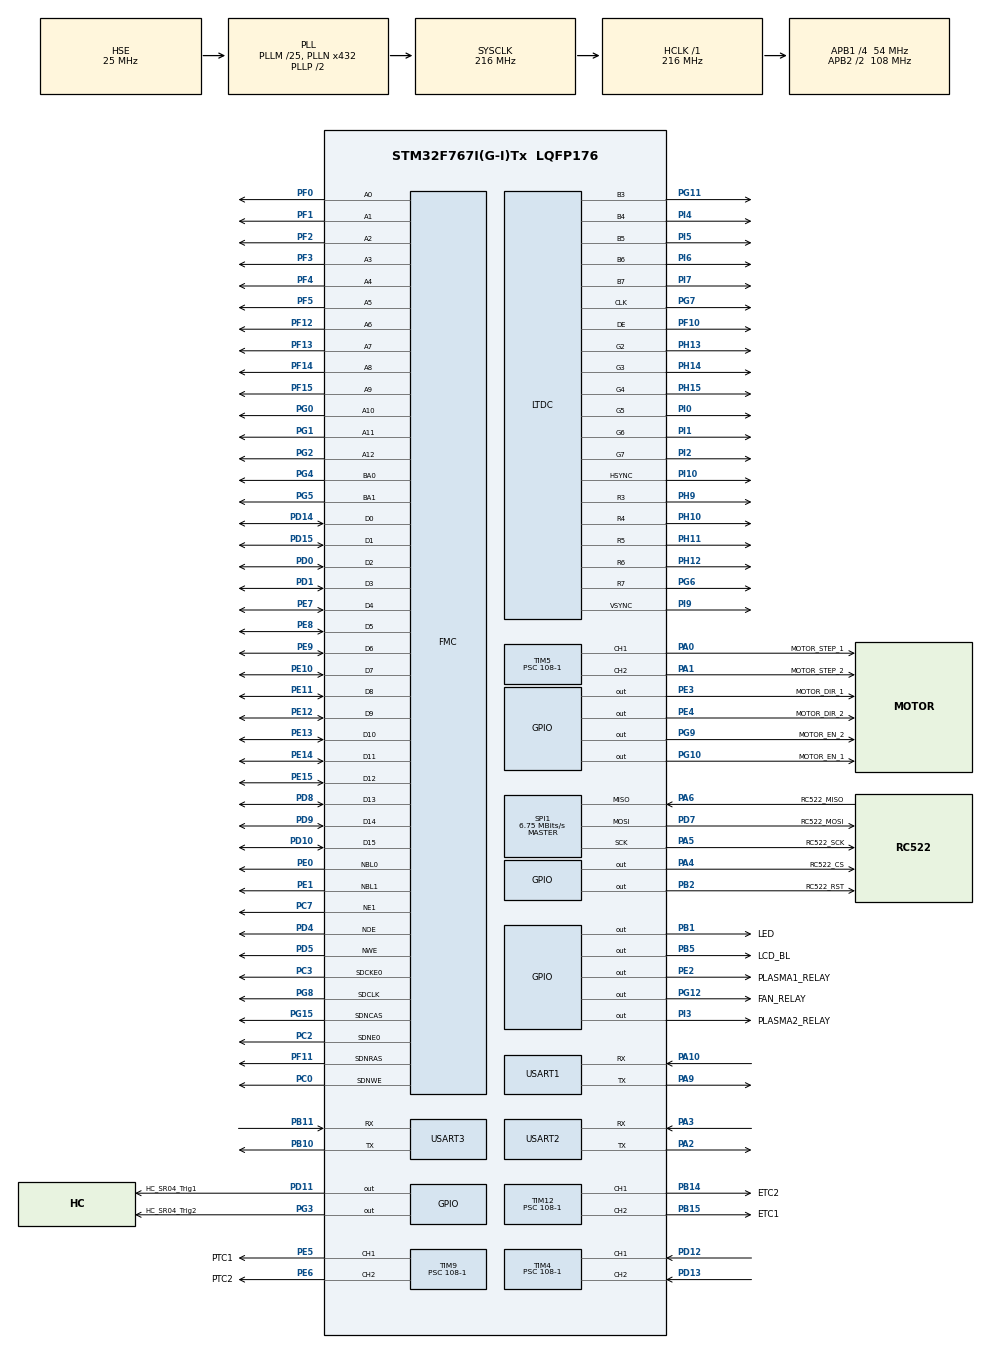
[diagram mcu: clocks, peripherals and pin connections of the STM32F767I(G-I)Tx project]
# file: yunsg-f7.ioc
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CORTEX_M7.CPU_DCache=Enabled
CORTEX_M7.CPU_ICache=Enabled
CORTEX_M7.Enable_Spec=__NULL
CORTEX_M7.MPU_Control=__NULL
CORTEX_M7.default_mode_Activation=1
DMA2D.ColorMode=DMA2D_OUTPUT_RGB565
Dma.Request0=USART2_RX
Dma.Request1=USART2_TX
Dma.USART2_RX.0.Direction=DMA_PERIPH_TO_MEMORY
Dma.USART2_RX.0.FIFOMode=DMA_FIFOMODE_DISABLE
Dma.USART2_RX.0.Instance=DMA1_Stream5
Dma.USART2_RX.0.MemDataAlignment=DMA_MDATAALIGN_BYTE
Dma.USART2_RX.0.MemInc=DMA_MINC_ENABLE
Dma.USART2_RX.0.Mode=DMA_NORMAL
Dma.USART2_RX.0.PeriphDataAlignment=DMA_PDATAALIGN_BYTE
Dma.USART2_RX.0.PeriphInc=DMA_PINC_DISABLE
Dma.USART2_RX.0.Priority=DMA_PRIORITY_LOW
Dma.USART2_TX.1.Direction=DMA_MEMORY_TO_PERIPH
Dma.USART2_TX.1.FIFOMode=DMA_FIFOMODE_DISABLE
Dma.USART2_TX.1.Instance=DMA1_Stream6
Dma.USART2_TX.1.MemDataAlignment=DMA_MDATAALIGN_BYTE
Dma.USART2_TX.1.MemInc=DMA_MINC_ENABLE
Dma.USART2_TX.1.Mode=DMA_NORMAL
Dma.USART2_TX.1.PeriphDataAlignment=DMA_PDATAALIGN_BYTE
Dma.USART2_TX.1.PeriphInc=DMA_PINC_DISABLE
Dma.USART2_TX.1.Priority=DMA_PRIORITY_LOW
FMC.AddressSetupTime1=0x0F
FMC.BusTurnAroundDuration1=0
FMC.CASLatency1=FMC_SDRAM_CAS_LATENCY_3
FMC.ColumnBitsNumber1=FMC_SDRAM_COLUMN_BITS_NUM_9
FMC.DataSetupTime1=80
FMC.ExitSelfRefreshDelay1=8
FMC.ExtendedAddressSetupTime1=0x0F
FMC.ExtendedBusTurnAroundDuration1=0
FMC.ExtendedDataSetupTime1=0x0F
FMC.ExtendedMode1=FMC_EXTENDED_MODE_ENABLE
FMC.LoadToActiveDelay1=2
FMC.RCDDelay1=2
FMC.RPDelay1=2
FMC.ReadBurst1=FMC_SDRAM_RBURST_ENABLE
FMC.ReadPipeDelay1=FMC_SDRAM_RPIPE_DELAY_1
FMC.RowCycleDelay1=6
FMC.SDClockPeriod1=FMC_SDRAM_CLOCK_PERIOD_2
FMC.SelfRefreshTime1=6
FMC.WriteFifo1=FMC_WRITE_FIFO_DISABLE
FMC.WriteRecoveryTime1=4
FREERTOS.Tasks01=defaultTask,24,128,StartDefaultTask,Default,NULL,Dynamic,NULL,NULL
IWDG.Prescaler=IWDG_PRESCALER_64
LTDC.ActiveW=800
LTDC.Alpha_L0=255
LTDC.FBStartAdress_L0=0xc0000000
LTDC.HBP=88
LTDC.HFP=40
LTDC.HSync=48
LTDC.ImageHeight_L0=480
LTDC.ImageWidth_L0=800
LTDC.Layers=0
LTDC.PixelFormat_L0=LTDC_PIXEL_FORMAT_RGB565
LTDC.VBP=32
LTDC.VFP=13
LTDC.VSync=3
LTDC.WindowX1_L0=800
LTDC.WindowY1_L0=480
Mcu.Family=STM32F7
Mcu.Name=STM32F767I(G-I)Tx
Mcu.Package=LQFP176
NVIC.DMA1_Stream5_IRQn=true\:5\:0\:false\:false\:true\:true\:false\:true\:true
NVIC.DMA1_Stream6_IRQn=true\:5\:0\:false\:false\:true\:true\:false\:true\:true
NVIC.DMA2D_IRQn=true\:5\:0\:false\:false\:true\:true\:true\:true\:true
NVIC.LTDC_IRQn=true\:5\:0\:false\:false\:true\:true\:true\:true\:true
NVIC.PriorityGroup=NVIC_PRIORITYGROUP_4
NVIC.TIM1_UP_TIM10_IRQn=true\:15\:0\:false\:false\:true\:false\:false\:true\:true
NVIC.TIM2_IRQn=true\:5\:0\:false\:false\:true\:true\:true\:true\:true
NVIC.TIM4_IRQn=true\:5\:0\:true\:false\:true\:true\:true\:true\:true
NVIC.TimeBase=TIM1_UP_TIM10_IRQn
NVIC.TimeBaseIP=TIM1
NVIC.USART2_IRQn=true\:5\:0\:false\:false\:true\:true\:true\:true\:true
NVIC.USART3_IRQn=true\:5\:0\:false\:false\:true\:true\:true\:true\:true
PA0/WKUP.GPIO_Label=MOTOR_STEP_1
PA0/WKUP.Signal=S_TIM5_CH1
PA1.GPIO_Label=MOTOR_STEP_2
PA1.Signal=S_TIM5_CH2
PA10.Mode=Asynchronous
PA10.Signal=USART1_RX
PA13.Mode=Serial_Wire
PA13.Signal=SYS_JTMS-SWDIO
PA14.Mode=Serial_Wire
PA14.Signal=SYS_JTCK-SWCLK
PA2.Mode=Asynchronous
PA2.Signal=USART2_TX
PA3.Mode=Asynchronous
PA3.Signal=USART2_RX
PA4.GPIO_Label=RC522_CS
PA4.Signal=GPIO_Output
PA5.GPIO_Label=RC522_SCK
PA5.Mode=Full_Duplex_Master
PA5.Signal=SPI1_SCK
PA6.GPIO_Label=RC522_MISO
PA6.Mode=Full_Duplex_Master
PA6.Signal=SPI1_MISO
PA9.Mode=Asynchronous
PA9.Signal=USART1_TX
PB1.GPIO_Label=LED
PB1.Signal=GPIO_Output
PB10.Mode=Asynchronous
PB10.Signal=USART3_TX
PB11.Mode=Asynchronous
PB11.Signal=USART3_RX
PB14.GPIO_Label=ETC2
PB14.Signal=S_TIM12_CH1
PB15.GPIO_Label=ETC1
PB15.Signal=S_TIM12_CH2
PB2.GPIO_Label=RC522_RST
PB2.Signal=GPIO_Output
PB5.GPIO_Label=LCD_BL
PB5.GPIO_Speed=GPIO_SPEED_FREQ_HIGH
PB5.Signal=GPIO_Output
PC0.Signal=FMC_SDNWE
PC1.GPIO_Label=ULTRAVIOLET_SENSOR
PC1.Signal=ADCx_IN11
PC14/OSC32_IN.Mode=LSE-External-Oscillator
PC14/OSC32_IN.Signal=RCC_OSC32_IN
PC15/OSC32_OUT.Mode=LSE-External-Oscillator
PC15/OSC32_OUT.Signal=RCC_OSC32_OUT
PC2.Mode=SdramChipSelect1_1
PC2.Signal=FMC_SDNE0
PC3.Mode=SdramChipSelect1_1
PC3.Signal=FMC_SDCKE0
PC7.Mode=NorPsramChipSelect1_1
PC7.Signal=FMC_NE1
PD0.Signal=FMC_D2_DA2
PD1.Signal=FMC_D3_DA3
PD10.Signal=FMC_D15_DA15
PD11.GPIO_Label=HC_SR04_Trig1
PD11.Signal=GPIO_Output
PD12.Signal=S_TIM4_CH1
PD13.Signal=S_TIM4_CH2
PD14.Signal=FMC_D0_DA0
PD15.Signal=FMC_D1_DA1
PD4.Signal=FMC_NOE
PD5.Signal=FMC_NWE
PD7.GPIO_Label=RC522_MOSI
PD7.Mode=Full_Duplex_Master
PD7.Signal=SPI1_MOSI
PD8.Signal=FMC_D13_DA13
PD9.Signal=FMC_D14_DA14
PE0.Signal=FMC_NBL0
PE1.Signal=FMC_NBL1
PE10.Signal=FMC_D7_DA7
PE11.Signal=FMC_D8_DA8
PE12.Signal=FMC_D9_DA9
PE13.Signal=FMC_D10_DA10
PE14.Signal=FMC_D11_DA11
PE15.Signal=FMC_D12_DA12
PE2.GPIO_Label=PLASMA1_RELAY
PE2.GPIO_ModeDefaultOutputPP=GPIO_MODE_OUTPUT_OD
PE2.GPIO_PuPd=GPIO_NOPULL
PE2.PinState=GPIO_PIN_SET
PE2.Signal=GPIO_Output
PE3.GPIO_Label=MOTOR_DIR_1
PE3.Signal=GPIO_Output
PE4.GPIO_Label=MOTOR_DIR_2
PE4.Signal=GPIO_Output
PE5.GPIO_Label=PTC1
PE5.Signal=S_TIM9_CH1
PE6.GPIO_Label=PTC2
PE6.Signal=S_TIM9_CH2
PE7.Signal=FMC_D4_DA4
PE8.Signal=FMC_D5_DA5
PE9.Signal=FMC_D6_DA6
PF0.Signal=FMC_A0
PF1.Signal=FMC_A1
PF10.GPIO_Speed=GPIO_SPEED_FREQ_VERY_HIGH
PF10.Mode=RGB565
PF10.Signal=LTDC_DE
PF11.Signal=FMC_SDNRAS
PF12.Signal=FMC_A6
PF13.Signal=FMC_A7
PF14.Signal=FMC_A8
PF15.Signal=FMC_A9
PF2.Signal=FMC_A2
PF3.Signal=FMC_A3
PF4.Signal=FMC_A4
PF5.Signal=FMC_A5
PG0.Signal=FMC_A10
PG1.Signal=FMC_A11
PG10.GPIO_Label=MOTOR_EN_1
PG10.Signal=GPIO_Output
PG11.GPIO_Speed=GPIO_SPEED_FREQ_VERY_HIGH
PG11.Mode=RGB565
PG11.Signal=LTDC_B3
PG12.GPIO_Label=FAN_RELAY
PG12.GPIO_ModeDefaultOutputPP=GPIO_MODE_OUTPUT_OD
PG12.GPIO_PuPd=GPIO_NOPULL
PG12.PinState=GPIO_PIN_SET
PG12.Signal=GPIO_Output
PG15.Signal=FMC_SDNCAS
PG2.Signal=FMC_A12
PG3.GPIO_Label=HC_SR04_Trig2
PG3.Signal=GPIO_Output
PG4.Signal=FMC_A14_BA0
PG5.Signal=FMC_A15_BA1
PG6.GPIO_Speed=GPIO_SPEED_FREQ_VERY_HIGH
PG6.Mode=RGB565
PG6.Signal=LTDC_R7
PG7.GPIO_Speed=GPIO_SPEED_FREQ_VERY_HIGH
PG7.Mode=RGB565
PG7.Signal=LTDC_CLK
PG8.Signal=FMC_SDCLK
PG9.GPIO_Label=MOTOR_EN_2
PG9.Signal=GPIO_Output
PH0/OSC_IN.Mode=HSE-External-Oscillator
PH0/OSC_IN.Signal=RCC_OSC_IN
PH1/OSC_OUT.Mode=HSE-External-Oscillator
PH1/OSC_OUT.Signal=RCC_OSC_OUT
PH10.GPIO_Speed=GPIO_SPEED_FREQ_VERY_HIGH
PH10.Mode=RGB565
PH10.Signal=LTDC_R4
PH11.GPIO_Speed=GPIO_SPEED_FREQ_VERY_HIGH
PH11.Mode=RGB565
PH11.Signal=LTDC_R5
PH12.GPIO_Speed=GPIO_SPEED_FREQ_VERY_HIGH
PH12.Mode=RGB565
PH12.Signal=LTDC_R6
PH13.GPIO_Speed=GPIO_SPEED_FREQ_VERY_HIGH
PH13.Mode=RGB565
PH13.Signal=LTDC_G2
PH14.GPIO_Speed=GPIO_SPEED_FREQ_VERY_HIGH
PH14.Mode=RGB565
PH14.Signal=LTDC_G3
PH15.GPIO_Speed=GPIO_SPEED_FREQ_VERY_HIGH
PH15.Mode=RGB565
PH15.Signal=LTDC_G4
PH9.GPIO_Speed=GPIO_SPEED_FREQ_VERY_HIGH
PH9.Mode=RGB565
PH9.Signal=LTDC_R3
PI0.GPIO_Speed=GPIO_SPEED_FREQ_VERY_HIGH
PI0.Mode=RGB565
PI0.Signal=LTDC_G5
PI1.GPIO_Speed=GPIO_SPEED_FREQ_VERY_HIGH
PI1.Mode=RGB565
PI1.Signal=LTDC_G6
PI10.GPIO_Speed=GPIO_SPEED_FREQ_VERY_HIGH
PI10.Mode=RGB565
PI10.Signal=LTDC_HSYNC
PI2.GPIO_Speed=GPIO_SPEED_FREQ_VERY_HIGH
PI2.Mode=RGB565
PI2.Signal=LTDC_G7
PI3.GPIO_Label=PLASMA2_RELAY
PI3.GPIO_ModeDefaultOutputPP=GPIO_MODE_OUTPUT_OD
PI3.GPIO_PuPd=GPIO_NOPULL
PI3.GPIO_Speed=GPIO_SPEED_FREQ_MEDIUM
PI3.PinState=GPIO_PIN_SET
PI3.Signal=GPIO_Output
PI4.GPIO_Speed=GPIO_SPEED_FREQ_VERY_HIGH
PI4.Mode=RGB565
PI4.Signal=LTDC_B4
PI5.GPIO_Speed=GPIO_SPEED_FREQ_VERY_HIGH
PI5.Mode=RGB565
PI5.Signal=LTDC_B5
PI6.GPIO_Speed=GPIO_SPEED_FREQ_VERY_HIGH
PI6.Mode=RGB565
PI6.Signal=LTDC_B6
PI7.GPIO_Speed=GPIO_SPEED_FREQ_VERY_HIGH
PI7.Mode=RGB565
PI7.Signal=LTDC_B7
PI9.GPIO_Speed=GPIO_SPEED_FREQ_VERY_HIGH
PI9.Mode=RGB565
PI9.Signal=LTDC_VSYNC
ProjectManager.HeapSize=0x200
ProjectManager.StackSize=0x1000
ProjectManager.TargetToolchain=Makefile
RCC.AHBFreq_Value=216000000
RCC.APB1CLKDivider=RCC_HCLK_DIV4
RCC.APB1Freq_Value=54000000
RCC.APB1TimFreq_Value=108000000
RCC.APB2CLKDivider=RCC_HCLK_DIV2
RCC.APB2Freq_Value=108000000
RCC.APB2TimFreq_Value=216000000
RCC.CortexFreq_Value=216000000
RCC.HCLKFreq_Value=216000000
RCC.HSE_VALUE=25000000
RCC.HSI_VALUE=16000000
RCC.PLLM=25
RCC.PLLN=432
RCC.PLLSourceVirtual=RCC_PLLSOURCE_HSE
RCC.SYSCLKFreq_VALUE=216000000
RCC.SYSCLKSource=RCC_SYSCLKSOURCE_PLLCLK
RCC.USBFreq_Value=216000000
RCC.VCOOutputFreq_Value=432000000
SH.ADCx_IN11.0=ADC1_IN11
SH.FMC_A0.0=FMC_A0,13b-sda1
SH.FMC_A1.0=FMC_A1,13b-sda1
SH.FMC_A10.0=FMC_A10,13b-sda1
SH.FMC_A11.0=FMC_A11,13b-sda1
SH.FMC_A12.0=FMC_A12,13b-sda1
SH.FMC_A14_BA0.0=FMC_BA0,FourSdramBanks1
SH.FMC_A15_BA1.0=FMC_BA1,FourSdramBanks1
SH.FMC_A2.0=FMC_A2,13b-sda1
SH.FMC_A3.0=FMC_A3,13b-sda1
SH.FMC_A4.0=FMC_A4,13b-sda1
SH.FMC_A5.0=FMC_A5,13b-sda1
SH.FMC_A6.0=FMC_A6,13b-sda1
SH.FMC_A6.1=FMC_A6,A6_1
SH.FMC_A7.0=FMC_A7,13b-sda1
SH.FMC_A8.0=FMC_A8,13b-sda1
SH.FMC_A9.0=FMC_A9,13b-sda1
SH.FMC_D0_DA0.0=FMC_D0,sd-16b-d1
SH.FMC_D0_DA0.1=FMC_D0,16b-d1
SH.FMC_D10_DA10.0=FMC_D10,sd-16b-d1
SH.FMC_D10_DA10.1=FMC_D10,16b-d1
SH.FMC_D11_DA11.0=FMC_D11,sd-16b-d1
SH.FMC_D11_DA11.1=FMC_D11,16b-d1
SH.FMC_D12_DA12.0=FMC_D12,sd-16b-d1
SH.FMC_D12_DA12.1=FMC_D12,16b-d1
SH.FMC_D13_DA13.0=FMC_D13,sd-16b-d1
SH.FMC_D13_DA13.1=FMC_D13,16b-d1
SH.FMC_D14_DA14.0=FMC_D14,sd-16b-d1
SH.FMC_D14_DA14.1=FMC_D14,16b-d1
SH.FMC_D15_DA15.0=FMC_D15,sd-16b-d1
SH.FMC_D15_DA15.1=FMC_D15,16b-d1
SH.FMC_D1_DA1.0=FMC_D1,sd-16b-d1
SH.FMC_D1_DA1.1=FMC_D1,16b-d1
SH.FMC_D2_DA2.0=FMC_D2,sd-16b-d1
SH.FMC_D2_DA2.1=FMC_D2,16b-d1
SH.FMC_D3_DA3.0=FMC_D3,sd-16b-d1
SH.FMC_D3_DA3.1=FMC_D3,16b-d1
SH.FMC_D4_DA4.0=FMC_D4,sd-16b-d1
SH.FMC_D4_DA4.1=FMC_D4,16b-d1
SH.FMC_D5_DA5.0=FMC_D5,sd-16b-d1
SH.FMC_D5_DA5.1=FMC_D5,16b-d1
SH.FMC_D6_DA6.0=FMC_D6,sd-16b-d1
SH.FMC_D6_DA6.1=FMC_D6,16b-d1
SH.FMC_D7_DA7.0=FMC_D7,sd-16b-d1
SH.FMC_D7_DA7.1=FMC_D7,16b-d1
SH.FMC_D8_DA8.0=FMC_D8,sd-16b-d1
SH.FMC_D8_DA8.1=FMC_D8,16b-d1
SH.FMC_D9_DA9.0=FMC_D9,sd-16b-d1
SH.FMC_D9_DA9.1=FMC_D9,16b-d1
SH.FMC_NBL0.0=FMC_NBL0,Sd2ByteEnable1
SH.FMC_NBL1.0=FMC_NBL1,Sd2ByteEnable1
SH.FMC_NOE.0=FMC_NOE,Lcd1
SH.FMC_NWE.0=FMC_NWE,Lcd1
SH.FMC_SDCLK.0=FMC_SDCLK,13b-sda1
SH.FMC_SDNCAS.0=FMC_SDNCAS,13b-sda1
SH.FMC_SDNRAS.0=FMC_SDNRAS,13b-sda1
SH.FMC_SDNWE.0=FMC_SDNWE,13b-sda1
SH.S_TIM12_CH1.0=TIM12_CH1,PWM Generation1 CH1
SH.S_TIM12_CH2.0=TIM12_CH2,PWM Generation2 CH2
SH.S_TIM4_CH1.0=TIM4_CH1,Input_Capture1_from_TI1
SH.S_TIM4_CH2.0=TIM4_CH2,Input_Capture2_from_TI2
SH.S_TIM5_CH1.0=TIM5_CH1,PWM Generation1 CH1
SH.S_TIM5_CH2.0=TIM5_CH2,PWM Generation2 CH2
SH.S_TIM9_CH1.0=TIM9_CH1,PWM Generation1 CH1
SH.S_TIM9_CH2.0=TIM9_CH2,PWM Generation2 CH2
SPI1.BaudRatePrescaler=SPI_BAUDRATEPRESCALER_16
SPI1.CalculateBaudRate=6.75 MBits/s
SPI1.DataSize=SPI_DATASIZE_8BIT
SPI1.Direction=SPI_DIRECTION_2LINES
SPI1.Mode=SPI_MODE_MASTER
SPI1.VirtualType=VM_MASTER
TIM12.Channel-PWM\ Generation1\ CH1=TIM_CHANNEL_1
TIM12.Channel-PWM\ Generation2\ CH2=TIM_CHANNEL_2
TIM12.Period=1000-1
TIM12.Prescaler=108-1
TIM2.Period=18000000-1
TIM2.Prescaler=10800-1
TIM4.Channel-Input_Capture1_from_TI1=TIM_CHANNEL_1
TIM4.Channel-Input_Capture2_from_TI2=TIM_CHANNEL_2
TIM4.Prescaler=108-1
TIM5.Channel-PWM\ Generation1\ CH1=TIM_CHANNEL_1
TIM5.Channel-PWM\ Generation2\ CH2=TIM_CHANNEL_2
TIM5.Period=1000-1
TIM5.Prescaler=108-1
TIM5.Pulse-PWM\ Generation1\ CH1=500
TIM5.Pulse-PWM\ Generation2\ CH2=500
TIM9.Channel-PWM\ Generation1\ CH1=TIM_CHANNEL_1
TIM9.Channel-PWM\ Generation2\ CH2=TIM_CHANNEL_2
TIM9.Period=1000-1
TIM9.Prescaler=108-1
USART1.VirtualMode-Asynchronous=VM_ASYNC
USART2.VirtualMode-Asynchronous=VM_ASYNC
USART3.VirtualMode-Asynchronous=VM_ASYNC
VP_CRC_VS_CRC.Mode=CRC_Activate
VP_DMA2D_VS_DMA2D.Mode=DMA2D_Activate
VP_FREERTOS_VS_CMSIS_V2.Mode=CMSIS_V2
VP_IWDG_VS_IWDG.Mode=IWDG_Activate
VP_SYS_VS_tim1.Mode=TIM1
VP_TIM12_VS_ClockSourceINT.Mode=Internal
VP_TIM2_VS_ClockSourceINT.Mode=Internal
VP_TIM4_VS_ClockSourceINT.Mode=Internal
VP_TIM5_VS_ClockSourceINT.Mode=Internal
VP_TIM9_VS_ClockSourceINT.Mode=Internal
board=custom

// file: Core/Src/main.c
/* USER CODE BEGIN Header */
/**
 ******************************************************************************
 * @file           : main.c
 * @brief          : Main program body
 ******************************************************************************
 * @attention
 *
 * Copyright (c) 2025 STMicroelectronics.
 * All rights reserved.
 *
 * This software is licensed under terms that can be found in the LICENSE file
 * in the root directory of this software component.
 * If no LICENSE file comes with this software, it is provided AS-IS.
 *
 ******************************************************************************
 */
/* USER CODE END Header */
#include "main.h"
#include "cmsis_os.h"
#include "crc.h"
#include "dma.h"
#include "dma2d.h"
#include "iwdg.h"
#include "ltdc.h"
#include "spi.h"
#include "tim.h"
#include "usart.h"
#include "gpio.h"
#include "fmc.h"

void SystemClock_Config(void);
void MX_FREERTOS_Init(void);

int main(void)
{

  /* Enable the CPU Cache */

  /* Enable I-Cache---------------------------------------------------------*/
  SCB_EnableICache();

  /* Enable D-Cache---------------------------------------------------------*/
  SCB_EnableDCache();

  /* MCU Configuration--------------------------------------------------------*/

  /* Reset of all peripherals, Initializes the Flash interface and the Systick. */
  HAL_Init();

  /* Configure the system clock */
  SystemClock_Config();

  /* Initialize all configured peripherals */
  MX_GPIO_Init();
  MX_DMA_Init();
  MX_USART1_UART_Init();
  MX_DMA2D_Init();
  MX_FMC_Init();
  MX_LTDC_Init();
  MX_CRC_Init();
  MX_USART2_UART_Init();
  MX_TIM4_Init();
  MX_TIM5_Init();
  MX_SPI1_Init();
  MX_USART3_UART_Init();
  MX_TIM2_Init();
  MX_IWDG_Init();
  MX_TIM12_Init();
  MX_TIM9_Init();

  /* Init scheduler */
  osKernelInitialize();

  /* Call init function for freertos objects (in cmsis_os2.c) */
  MX_FREERTOS_Init();

  /* Start scheduler */
  osKernelStart();

  /* We should never get here as control is now taken by the scheduler */

  /* Infinite loop */
  while (1)
  {

  }
}

void SystemClock_Config(void)
{
  RCC_OscInitTypeDef RCC_OscInitStruct = {0};
  RCC_ClkInitTypeDef RCC_ClkInitStruct = {0};

  /** Configure LSE Drive Capability
  */
  HAL_PWR_EnableBkUpAccess();

  /** Configure the main internal regulator output voltage
  */
  __HAL_RCC_PWR_CLK_ENABLE();
  __HAL_PWR_VOLTAGESCALING_CONFIG(PWR_REGULATOR_VOLTAGE_SCALE1);

  /** Initializes the RCC Oscillators according to the specified parameters
  * in the RCC_OscInitTypeDef structure.
  */
  RCC_OscInitStruct.OscillatorType = RCC_OSCILLATORTYPE_LSI|RCC_OSCILLATORTYPE_HSE;
  RCC_OscInitStruct.HSEState = RCC_HSE_ON;
  RCC_OscInitStruct.LSIState = RCC_LSI_ON;
  RCC_OscInitStruct.PLL.PLLState = RCC_PLL_ON;
  RCC_OscInitStruct.PLL.PLLSource = RCC_PLLSOURCE_HSE;
  RCC_OscInitStruct.PLL.PLLM = 25;
  RCC_OscInitStruct.PLL.PLLN = 432;
  RCC_OscInitStruct.PLL.PLLP = RCC_PLLP_DIV2;
  RCC_OscInitStruct.PLL.PLLQ = 2;
  RCC_OscInitStruct.PLL.PLLR = 2;
  if (HAL_RCC_OscConfig(&RCC_OscInitStruct) != HAL_OK)
  {
    Error_Handler();
  }

  /** Activate the Over-Drive mode
  */
  if (HAL_PWREx_EnableOverDrive() != HAL_OK)
  {
    Error_Handler();
  }

  /** Initializes the CPU, AHB and APB buses clocks
  */
  RCC_ClkInitStruct.ClockType = RCC_CLOCKTYPE_HCLK|RCC_CLOCKTYPE_SYSCLK
                              |RCC_CLOCKTYPE_PCLK1|RCC_CLOCKTYPE_PCLK2;
  RCC_ClkInitStruct.SYSCLKSource = RCC_SYSCLKSOURCE_PLLCLK;
  RCC_ClkInitStruct.AHBCLKDivider = RCC_SYSCLK_DIV1;
  RCC_ClkInitStruct.APB1CLKDivider = RCC_HCLK_DIV4;
  RCC_ClkInitStruct.APB2CLKDivider = RCC_HCLK_DIV2;

  if (HAL_RCC_ClockConfig(&RCC_ClkInitStruct, FLASH_LATENCY_7) != HAL_OK)
  {
    Error_Handler();
  }
}

/* USER CODE BEGIN 4 */
#include "plasma.h"
/* USER CODE END 4 */

void HAL_TIM_PeriodElapsedCallback(TIM_HandleTypeDef *htim)
{
  if (htim->Instance == TIM1)
  {
    HAL_IncTick();
  }
  /* USER CODE BEGIN Callback 1 */
  if(htim->Instance==TIM2)
  {
    plasma_disable();
  }
  /* USER CODE END Callback 1 */
}

void Error_Handler(void)
{
  __disable_irq();
  while (1)
  {
  }
}

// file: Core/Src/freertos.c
/* USER CODE BEGIN Header */
/**
 ******************************************************************************
 * File Name          : freertos.c
 * Description        : Code for freertos applications
 ******************************************************************************
 * @attention
 *
 * Copyright (c) 2025 STMicroelectronics.
 * All rights reserved.
 *
 * This software is licensed under terms that can be found in the LICENSE file
 * in the root directory of this software component.
 * If no LICENSE file comes with this software, it is provided AS-IS.
 *
 ******************************************************************************
 */
/* USER CODE END Header */

#include "FreeRTOS.h"
#include "task.h"
#include "main.h"
#include "cmsis_os.h"

/* USER CODE BEGIN Includes */
#include "user_TaskInit.h"
/* USER CODE END Includes */

/* Definitions for defaultTask */
osThreadId_t defaultTaskHandle;
const osThreadAttr_t defaultTask_attributes = {
  .name = "defaultTask",
  .stack_size = 128 * 4,
  .priority = (osPriority_t) osPriorityNormal,
};

void StartDefaultTask(void *argument);

void MX_FREERTOS_Init(void); /* (MISRA C 2004 rule 8.1) */

void MX_FREERTOS_Init(void) {
  /* USER CODE BEGIN Init */
  user_tasks_init();
  /* USER CODE END Init */

  /* Create the thread(s) */
  /* creation of defaultTask */
  defaultTaskHandle = osThreadNew(StartDefaultTask, NULL, &defaultTask_attributes);

}

void StartDefaultTask(void *argument)
{
  /* USER CODE BEGIN StartDefaultTask */

  /* Infinite loop */
  for (;;)
  {
    HAL_GPIO_TogglePin(GPIOB,GPIO_PIN_1);
    osDelay(500);
  }
  /* USER CODE END StartDefaultTask */
}
